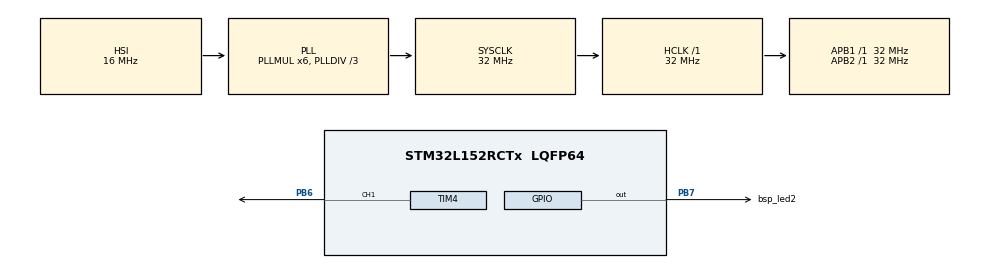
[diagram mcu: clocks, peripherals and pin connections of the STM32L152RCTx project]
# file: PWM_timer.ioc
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Mcu.Family=STM32L1
Mcu.Name=STM32L152RCTx
Mcu.Package=LQFP64
NVIC.PriorityGroup=NVIC_PRIORITYGROUP_0
PB6.Signal=S_TIM4_CH1
PB7.GPIO_Label=bsp_led2
PB7.Signal=GPIO_Output
ProjectManager.HeapSize=0x200
ProjectManager.StackSize=0x400
ProjectManager.TargetToolchain=STM32CubeIDE
RCC.48MHZClocksFreq_Value=48000000
RCC.AHBFreq_Value=32000000
RCC.APB1Freq_Value=32000000
RCC.APB1TimFreq_Value=32000000
RCC.APB2Freq_Value=32000000
RCC.APB2TimFreq_Value=32000000
RCC.HCLKFreq_Value=32000000
RCC.HSE_VALUE=8000000
RCC.HSI_VALUE=16000000
RCC.LSE_VALUE=32768
RCC.MSI_VALUE=2097000
RCC.PLLDIV=RCC_PLL_DIV3
RCC.PLLMUL=RCC_PLL_MUL6
RCC.RTCClockSelectionVirtual=RCC_RTCCLKSOURCE_LSE
RCC.SYSCLKFreq_VALUE=32000000
RCC.SYSCLKSource=RCC_SYSCLKSOURCE_PLLCLK
RCC.USBOutput=48000000
RCC.VCOOutputFreq_Value=96000000
SH.S_TIM4_CH1.0=TIM4_CH1,PWM Generation1 CH1
TIM4.AutoReloadPreload=TIM_AUTORELOAD_PRELOAD_DISABLE
TIM4.Channel-PWM\ Generation1\ CH1=TIM_CHANNEL_1
TIM4.Period=99
TIM4.Prescaler=32
TIM4.Pulse-PWM\ Generation1\ CH1=0
VP_TIM4_VS_ClockSourceINT.Mode=Internal
board=STM32L152C-DISCO

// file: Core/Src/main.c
/* USER CODE BEGIN Header */
/**
  ******************************************************************************
  * @file           : main.c
  * @brief          : Main program body
  ******************************************************************************
  * @attention
  *
  * Copyright (c) 2023 STMicroelectronics.
  * All rights reserved.
  *
  * This software is licensed under terms that can be found in the LICENSE file
  * in the root directory of this software component.
  * If no LICENSE file comes with this software, it is provided AS-IS.
  *
  ******************************************************************************
  */
/* USER CODE END Header */
#include "main.h"

TIM_HandleTypeDef htim4;

/* USER CODE BEGIN PV */
uint32_t i=0;

/* USER CODE END PV */

void SystemClock_Config(void);
static void MX_GPIO_Init(void);
static void MX_TIM4_Init(void);

int main(void)
{

  /* MCU Configuration--------------------------------------------------------*/

  /* Reset of all peripherals, Initializes the Flash interface and the Systick. */
  HAL_Init();

  /* Configure the system clock */
  SystemClock_Config();

  /* Initialize all configured peripherals */
  MX_GPIO_Init();
  MX_TIM4_Init();
  /* USER CODE BEGIN 2 */

 //TIM4->CCR1=0;
  HAL_TIM_PWM_Start(&htim4, TIM_CHANNEL_1);
  /* USER CODE END 2 */

  /* Infinite loop */
  while (1)
  {

    /* USER CODE BEGIN 3 */
	  for( i=0;i<100;i++)
	  {
		  TIM4->CCR1=i;
		  HAL_Delay(50);
	  }
	  for( i=100;i>0;i--)
	  	  {
	  		  TIM4->CCR1=i;
	  		 HAL_Delay(50);
	  	  }

  }
  /* USER CODE END 3 */
}

void SystemClock_Config(void)
{
  RCC_OscInitTypeDef RCC_OscInitStruct = {0};
  RCC_ClkInitTypeDef RCC_ClkInitStruct = {0};

  /** Configure the main internal regulator output voltage
  */
  __HAL_PWR_VOLTAGESCALING_CONFIG(PWR_REGULATOR_VOLTAGE_SCALE1);

  /** Initializes the RCC Oscillators according to the specified parameters
  * in the RCC_OscInitTypeDef structure.
  */
  RCC_OscInitStruct.OscillatorType = RCC_OSCILLATORTYPE_HSI;
  RCC_OscInitStruct.HSIState = RCC_HSI_ON;
  RCC_OscInitStruct.HSICalibrationValue = RCC_HSICALIBRATION_DEFAULT;
  RCC_OscInitStruct.PLL.PLLState = RCC_PLL_ON;
  RCC_OscInitStruct.PLL.PLLSource = RCC_PLLSOURCE_HSI;
  RCC_OscInitStruct.PLL.PLLMUL = RCC_PLL_MUL6;
  RCC_OscInitStruct.PLL.PLLDIV = RCC_PLL_DIV3;
  if (HAL_RCC_OscConfig(&RCC_OscInitStruct) != HAL_OK)
  {
    Error_Handler();
  }

  /** Initializes the CPU, AHB and APB buses clocks
  */
  RCC_ClkInitStruct.ClockType = RCC_CLOCKTYPE_HCLK|RCC_CLOCKTYPE_SYSCLK
                              |RCC_CLOCKTYPE_PCLK1|RCC_CLOCKTYPE_PCLK2;
  RCC_ClkInitStruct.SYSCLKSource = RCC_SYSCLKSOURCE_PLLCLK;
  RCC_ClkInitStruct.AHBCLKDivider = RCC_SYSCLK_DIV1;
  RCC_ClkInitStruct.APB1CLKDivider = RCC_HCLK_DIV1;
  RCC_ClkInitStruct.APB2CLKDivider = RCC_HCLK_DIV1;

  if (HAL_RCC_ClockConfig(&RCC_ClkInitStruct, FLASH_LATENCY_1) != HAL_OK)
  {
    Error_Handler();
  }
}

static void MX_TIM4_Init(void)
{

  TIM_ClockConfigTypeDef sClockSourceConfig = {0};
  TIM_MasterConfigTypeDef sMasterConfig = {0};
  TIM_OC_InitTypeDef sConfigOC = {0};

  htim4.Instance = TIM4;
  htim4.Init.Prescaler = 32;
  htim4.Init.CounterMode = TIM_COUNTERMODE_UP;
  htim4.Init.Period = 99;
  htim4.Init.ClockDivision = TIM_CLOCKDIVISION_DIV1;
  htim4.Init.AutoReloadPreload = TIM_AUTORELOAD_PRELOAD_DISABLE;
  if (HAL_TIM_Base_Init(&htim4) != HAL_OK)
  {
    Error_Handler();
  }
  sClockSourceConfig.ClockSource = TIM_CLOCKSOURCE_INTERNAL;
  if (HAL_TIM_ConfigClockSource(&htim4, &sClockSourceConfig) != HAL_OK)
  {
    Error_Handler();
  }
  if (HAL_TIM_PWM_Init(&htim4) != HAL_OK)
  {
    Error_Handler();
  }
  sMasterConfig.MasterOutputTrigger = TIM_TRGO_RESET;
  sMasterConfig.MasterSlaveMode = TIM_MASTERSLAVEMODE_DISABLE;
  if (HAL_TIMEx_MasterConfigSynchronization(&htim4, &sMasterConfig) != HAL_OK)
  {
    Error_Handler();
  }
  sConfigOC.OCMode = TIM_OCMODE_PWM1;
  sConfigOC.Pulse = 0;
  sConfigOC.OCPolarity = TIM_OCPOLARITY_HIGH;
  sConfigOC.OCFastMode = TIM_OCFAST_DISABLE;
  if (HAL_TIM_PWM_ConfigChannel(&htim4, &sConfigOC, TIM_CHANNEL_1) != HAL_OK)
  {
    Error_Handler();
  }
  HAL_TIM_MspPostInit(&htim4);

}

static void MX_GPIO_Init(void)
{
  GPIO_InitTypeDef GPIO_InitStruct = {0};

  /* GPIO Ports Clock Enable */
  __HAL_RCC_GPIOB_CLK_ENABLE();

  /*Configure GPIO pin Output Level */
  HAL_GPIO_WritePin(bsp_led2_GPIO_Port, bsp_led2_Pin, GPIO_PIN_RESET);

  /*Configure GPIO pin : bsp_led2_Pin */
  GPIO_InitStruct.Pin = bsp_led2_Pin;
  GPIO_InitStruct.Mode = GPIO_MODE_OUTPUT_PP;
  GPIO_InitStruct.Pull = GPIO_NOPULL;
  GPIO_InitStruct.Speed = GPIO_SPEED_FREQ_LOW;
  HAL_GPIO_Init(bsp_led2_GPIO_Port, &GPIO_InitStruct);

}

void Error_Handler(void)
{
  __disable_irq();
  while (1)
  {
  }
}
